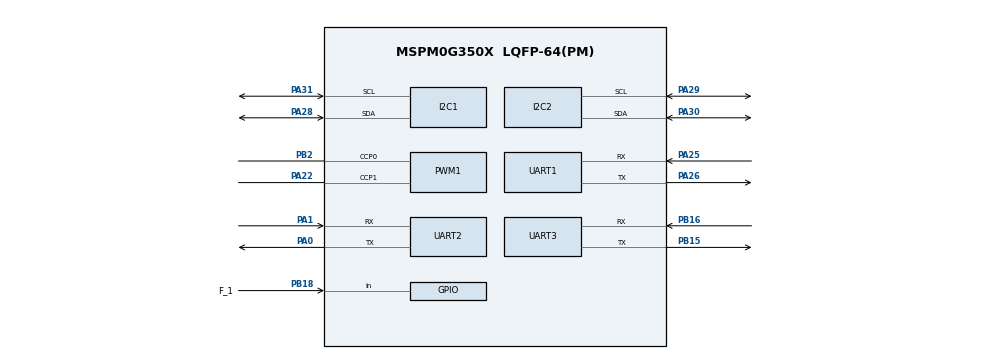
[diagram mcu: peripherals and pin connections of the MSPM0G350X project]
/**
 * @cliArgs --device "MSPM0G350X" --part "Default" --package "LQFP-64(PM)" --product "mspm0_sdk@2.04.00.06"
 * @versions {"tool":"1.24.0+4110"}
 */

/**
 * Import the modules used in this configuration.
 */
const GPIO    = scripting.addModule("/ti/driverlib/GPIO", {}, false);
const GPIO1   = GPIO.addInstance();
const GPIO2   = GPIO.addInstance();
const GPIO3   = GPIO.addInstance();
const GPIO4   = GPIO.addInstance();
const GPIO5   = GPIO.addInstance();
const GPIO6   = GPIO.addInstance();
const I2C     = scripting.addModule("/ti/driverlib/I2C", {}, false);
const I2C1    = I2C.addInstance();
const I2C2    = I2C.addInstance();
const PWM     = scripting.addModule("/ti/driverlib/PWM", {}, false);
const PWM1    = PWM.addInstance();
const SYSCTL  = scripting.addModule("/ti/driverlib/SYSCTL");
const SYSTICK = scripting.addModule("/ti/driverlib/SYSTICK");
const TIMER   = scripting.addModule("/ti/driverlib/TIMER", {}, false);
const TIMER1  = TIMER.addInstance();
const UART    = scripting.addModule("/ti/driverlib/UART", {}, false);
const UART1   = UART.addInstance();
const UART2   = UART.addInstance();
const UART3   = UART.addInstance();

/**
 * Write custom configuration values to the imported modules.
 */
const divider7       = system.clockTree["PLL_PDIV"];
divider7.divideValue = 8;

const divider9       = system.clockTree["UDIV"];
divider9.divideValue = 2;

const gate7  = system.clockTree["MFCLKGATE"];
gate7.enable = true;

const multiplier2         = system.clockTree["PLL_QDIV"];
multiplier2.multiplyValue = 40;

const mux8       = system.clockTree["HSCLKMUX"];
mux8.inputSelect = "HSCLKMUX_SYSPLL0";

const pinFunction4     = system.clockTree["HFXT"];
pinFunction4.inputFreq = 40;

GPIO1.$name                          = "GPIO_MOTOR_CONTROL";
GPIO1.associatedPins.create(4);
GPIO1.associatedPins[0].$name        = "left_IN1";
GPIO1.associatedPins[0].assignedPort = "PORTA";
GPIO1.associatedPins[0].assignedPin  = "12";
GPIO1.associatedPins[1].$name        = "left_IN2";
GPIO1.associatedPins[1].assignedPort = "PORTA";
GPIO1.associatedPins[1].assignedPin  = "13";
GPIO1.associatedPins[2].$name        = "right_IN1";
GPIO1.associatedPins[2].assignedPin  = "17";
GPIO1.associatedPins[2].assignedPort = "PORTA";
GPIO1.associatedPins[3].$name        = "right_IN2";
GPIO1.associatedPins[3].assignedPin  = "24";
GPIO1.associatedPins[3].assignedPort = "PORTA";

const Board = scripting.addModule("/ti/driverlib/Board", {}, false);

GPIO2.$name                               = "GPIO_ENCODER_L";
GPIO2.associatedPins.create(2);
GPIO2.associatedPins[0].direction         = "INPUT";
GPIO2.associatedPins[0].internalResistor  = "PULL_DOWN";
GPIO2.associatedPins[0].assignedPort      = "PORTB";
GPIO2.associatedPins[0].assignedPin       = "0";
GPIO2.associatedPins[0].interruptEn       = true;
GPIO2.associatedPins[0].interruptPriority = "0";
GPIO2.associatedPins[0].polarity          = "RISE";
GPIO2.associatedPins[0].$name             = "LEFT_A";
GPIO2.associatedPins[1].direction         = "INPUT";
GPIO2.associatedPins[1].internalResistor  = "PULL_DOWN";
GPIO2.associatedPins[1].assignedPort      = "PORTB";
GPIO2.associatedPins[1].assignedPin       = "14";
GPIO2.associatedPins[1].$name             = "LEFT_B";
GPIO2.associatedPins[1].interruptEn       = true;
GPIO2.associatedPins[1].interruptPriority = "0";
GPIO2.associatedPins[1].polarity          = "RISE";

GPIO3.$name                               = "GPIO_ENCODER_R";
GPIO3.associatedPins.create(2);
GPIO3.associatedPins[0].$name             = "RIGHT_A";
GPIO3.associatedPins[0].direction         = "INPUT";
GPIO3.associatedPins[0].internalResistor  = "PULL_DOWN";
GPIO3.associatedPins[0].interruptEn       = true;
GPIO3.associatedPins[0].interruptPriority = "0";
GPIO3.associatedPins[0].polarity          = "RISE";
GPIO3.associatedPins[0].assignedPort      = "PORTA";
GPIO3.associatedPins[0].assignedPin       = "7";
GPIO3.associatedPins[1].$name             = "RIGHT_B";
GPIO3.associatedPins[1].assignedPort      = "PORTB";
GPIO3.associatedPins[1].assignedPin       = "20";
GPIO3.associatedPins[1].direction         = "INPUT";
GPIO3.associatedPins[1].internalResistor  = "PULL_DOWN";
GPIO3.associatedPins[1].interruptEn       = true;
GPIO3.associatedPins[1].interruptPriority = "0";
GPIO3.associatedPins[1].polarity          = "RISE";

GPIO4.$name                              = "GPIO_CHOOSETOPIC";
GPIO4.associatedPins.create(2);
GPIO4.associatedPins[0].$name            = "Confirm";
GPIO4.associatedPins[0].direction        = "INPUT";
GPIO4.associatedPins[0].assignedPort     = "PORTB";
GPIO4.associatedPins[0].internalResistor = "PULL_UP";
GPIO4.associatedPins[0].assignedPin      = "4";
GPIO4.associatedPins[1].$name            = "ChooseStart";
GPIO4.associatedPins[1].direction        = "INPUT";
GPIO4.associatedPins[1].assignedPort     = "PORTB";
GPIO4.associatedPins[1].internalResistor = "PULL_UP";
GPIO4.associatedPins[1].assignedPin      = "5";

GPIO5.$name                               = "GPIO_GRAYSENSOR";
GPIO5.associatedPins.create(12);
GPIO5.associatedPins[0].$name             = "O1";
GPIO5.associatedPins[0].direction         = "INPUT";
GPIO5.associatedPins[0].internalResistor  = "PULL_DOWN";
GPIO5.associatedPins[0].assignedPort      = "PORTB";
GPIO5.associatedPins[0].assignedPin       = "27";
GPIO5.associatedPins[1].$name             = "O2";
GPIO5.associatedPins[1].direction         = "INPUT";
GPIO5.associatedPins[1].internalResistor  = "PULL_DOWN";
GPIO5.associatedPins[1].assignedPort      = "PORTB";
GPIO5.associatedPins[1].assignedPin       = "12";
GPIO5.associatedPins[2].$name             = "O3";
GPIO5.associatedPins[2].direction         = "INPUT";
GPIO5.associatedPins[2].assignedPort      = "PORTB";
GPIO5.associatedPins[2].internalResistor  = "PULL_DOWN";
GPIO5.associatedPins[2].assignedPin       = "13";
GPIO5.associatedPins[3].$name             = "O4";
GPIO5.associatedPins[3].direction         = "INPUT";
GPIO5.associatedPins[3].internalResistor  = "PULL_DOWN";
GPIO5.associatedPins[3].assignedPort      = "PORTB";
GPIO5.associatedPins[3].assignedPin       = "7";
GPIO5.associatedPins[4].$name             = "O5";
GPIO5.associatedPins[4].direction         = "INPUT";
GPIO5.associatedPins[4].internalResistor  = "PULL_DOWN";
GPIO5.associatedPins[4].assignedPort      = "PORTB";
GPIO5.associatedPins[4].assignedPin       = "9";
GPIO5.associatedPins[5].$name             = "O6";
GPIO5.associatedPins[5].direction         = "INPUT";
GPIO5.associatedPins[5].internalResistor  = "PULL_DOWN";
GPIO5.associatedPins[5].assignedPort      = "PORTB";
GPIO5.associatedPins[5].assignedPin       = "26";
GPIO5.associatedPins[6].$name             = "O7";
GPIO5.associatedPins[6].direction         = "INPUT";
GPIO5.associatedPins[6].internalResistor  = "PULL_DOWN";
GPIO5.associatedPins[6].assignedPort      = "PORTB";
GPIO5.associatedPins[6].assignedPin       = "17";
GPIO5.associatedPins[7].$name             = "O8";
GPIO5.associatedPins[7].direction         = "INPUT";
GPIO5.associatedPins[7].internalResistor  = "PULL_DOWN";
GPIO5.associatedPins[7].assignedPort      = "PORTB";
GPIO5.associatedPins[7].assignedPin       = "19";
GPIO5.associatedPins[8].$name             = "O9";
GPIO5.associatedPins[8].direction         = "INPUT";
GPIO5.associatedPins[8].internalResistor  = "PULL_DOWN";
GPIO5.associatedPins[8].assignedPort      = "PORTB";
GPIO5.associatedPins[8].assignedPin       = "21";
GPIO5.associatedPins[9].$name             = "O10";
GPIO5.associatedPins[9].direction         = "INPUT";
GPIO5.associatedPins[9].assignedPort      = "PORTB";
GPIO5.associatedPins[9].assignedPin       = "10";
GPIO5.associatedPins[9].internalResistor  = "PULL_DOWN";
GPIO5.associatedPins[10].$name            = "O11";
GPIO5.associatedPins[10].direction        = "INPUT";
GPIO5.associatedPins[10].internalResistor = "PULL_DOWN";
GPIO5.associatedPins[10].assignedPort     = "PORTB";
GPIO5.associatedPins[10].assignedPin      = "11";
GPIO5.associatedPins[11].$name            = "O12";
GPIO5.associatedPins[11].direction        = "INPUT";
GPIO5.associatedPins[11].assignedPort     = "PORTB";
GPIO5.associatedPins[11].assignedPin      = "24";
GPIO5.associatedPins[11].internalResistor = "PULL_DOWN";

GPIO6.$name                          = "GPIO_FUN";
GPIO6.associatedPins.create(2);
GPIO6.associatedPins[0].$name        = "F_1";
GPIO6.associatedPins[0].direction    = "INPUT";
GPIO6.associatedPins[0].assignedPort = "PORTB";
GPIO6.associatedPins[0].assignedPin  = "18";
GPIO6.associatedPins[0].pin.$assign  = "PB18";
GPIO6.associatedPins[1].$name        = "F_2";
GPIO6.associatedPins[1].direction    = "INPUT";
GPIO6.associatedPins[1].assignedPort = "PORTB";
GPIO6.associatedPins[1].assignedPin  = "22";

I2C1.$name                             = "I2C_MPU6050";
I2C1.basicEnableController             = true;
I2C1.basicControllerStandardBusSpeed   = "Fast";
I2C1.peripheral.sdaPin.$assign         = "PA28";
I2C1.peripheral.sclPin.$assign         = "PA31";
I2C1.sdaPinConfig.hideOutputInversion  = scripting.forceWrite(false);
I2C1.sdaPinConfig.onlyInternalResistor = scripting.forceWrite(false);
I2C1.sdaPinConfig.passedPeripheralType = scripting.forceWrite("Digital");
I2C1.sdaPinConfig.$name                = "ti_driverlib_gpio_GPIOPinGeneric10";
I2C1.sclPinConfig.hideOutputInversion  = scripting.forceWrite(false);
I2C1.sclPinConfig.onlyInternalResistor = scripting.forceWrite(false);
I2C1.sclPinConfig.passedPeripheralType = scripting.forceWrite("Digital");
I2C1.sclPinConfig.$name                = "ti_driverlib_gpio_GPIOPinGeneric11";

I2C2.$name                             = "I2C_OLED";
I2C2.basicEnableController             = true;
I2C2.basicControllerStandardBusSpeed   = "Fast";
I2C2.peripheral.sdaPin.$assign         = "PA30";
I2C2.peripheral.sclPin.$assign         = "PA29";
I2C2.sdaPinConfig.hideOutputInversion  = scripting.forceWrite(false);
I2C2.sdaPinConfig.onlyInternalResistor = scripting.forceWrite(false);
I2C2.sdaPinConfig.passedPeripheralType = scripting.forceWrite("Digital");
I2C2.sdaPinConfig.$name                = "ti_driverlib_gpio_GPIOPinGeneric12";
I2C2.sclPinConfig.hideOutputInversion  = scripting.forceWrite(false);
I2C2.sclPinConfig.onlyInternalResistor = scripting.forceWrite(false);
I2C2.sclPinConfig.passedPeripheralType = scripting.forceWrite("Digital");
I2C2.sclPinConfig.$name                = "ti_driverlib_gpio_GPIOPinGeneric13";

PWM1.$name                              = "Motor_PWM";
PWM1.timerCount                         = 2000;
PWM1.peripheral.$assign                 = "TIMG6";
PWM1.peripheral.ccp0Pin.$assign         = "PB2";
PWM1.peripheral.ccp1Pin.$assign         = "PA22";
PWM1.PWM_CHANNEL_0.$name                = "ti_driverlib_pwm_PWMTimerCC0";
PWM1.PWM_CHANNEL_1.$name                = "ti_driverlib_pwm_PWMTimerCC1";
PWM1.ccp0PinConfig.$name                = "ti_driverlib_gpio_GPIOPinGeneric4";
PWM1.ccp0PinConfig.direction            = scripting.forceWrite("OUTPUT");
PWM1.ccp0PinConfig.hideOutputInversion  = scripting.forceWrite(false);
PWM1.ccp0PinConfig.onlyInternalResistor = scripting.forceWrite(false);
PWM1.ccp0PinConfig.passedPeripheralType = scripting.forceWrite("Digital");
PWM1.ccp1PinConfig.$name                = "ti_driverlib_gpio_GPIOPinGeneric5";
PWM1.ccp1PinConfig.direction            = scripting.forceWrite("OUTPUT");
PWM1.ccp1PinConfig.hideOutputInversion  = scripting.forceWrite(false);
PWM1.ccp1PinConfig.onlyInternalResistor = scripting.forceWrite(false);
PWM1.ccp1PinConfig.passedPeripheralType = scripting.forceWrite("Digital");

SYSCTL.forceDefaultClkConfig = true;
SYSCTL.clockTreeEn           = true;

SYSTICK.periodEnable      = true;
SYSTICK.interruptEnable   = true;
SYSTICK.systickEnable     = true;
SYSTICK.interruptPriority = "1";
SYSTICK.period            = 80000;

TIMER1.$name = "TIMER_0";

UART1.enabledInterrupts                = ["RX"];
UART1.interruptPriority                = "0";
UART1.$name                            = "UART_k230";
UART1.uartClkSrc                       = "MFCLK";
UART1.targetBaudRate                   = 115200;
UART1.peripheral.$assign               = "UART3";
UART1.peripheral.rxPin.$assign         = "PA25";
UART1.peripheral.txPin.$assign         = "PA26";
UART1.txPinConfig.direction            = scripting.forceWrite("OUTPUT");
UART1.txPinConfig.hideOutputInversion  = scripting.forceWrite(false);
UART1.txPinConfig.onlyInternalResistor = scripting.forceWrite(false);
UART1.txPinConfig.passedPeripheralType = scripting.forceWrite("Digital");
UART1.txPinConfig.$name                = "ti_driverlib_gpio_GPIOPinGeneric0";
UART1.rxPinConfig.hideOutputInversion  = scripting.forceWrite(false);
UART1.rxPinConfig.onlyInternalResistor = scripting.forceWrite(false);
UART1.rxPinConfig.passedPeripheralType = scripting.forceWrite("Digital");
UART1.rxPinConfig.$name                = "ti_driverlib_gpio_GPIOPinGeneric1";

UART2.enabledInterrupts                = ["RX"];
UART2.$name                            = "UART_Debugger";
UART2.targetBaudRate                   = 115200;
UART2.peripheral.$assign               = "UART0";
UART2.peripheral.rxPin.$assign         = "PA1";
UART2.peripheral.txPin.$assign         = "PA0";
UART2.txPinConfig.direction            = scripting.forceWrite("OUTPUT");
UART2.txPinConfig.hideOutputInversion  = scripting.forceWrite(false);
UART2.txPinConfig.onlyInternalResistor = scripting.forceWrite(false);
UART2.txPinConfig.passedPeripheralType = scripting.forceWrite("Digital");
UART2.txPinConfig.$name                = "ti_driverlib_gpio_GPIOPinGeneric2";
UART2.rxPinConfig.hideOutputInversion  = scripting.forceWrite(false);
UART2.rxPinConfig.onlyInternalResistor = scripting.forceWrite(false);
UART2.rxPinConfig.passedPeripheralType = scripting.forceWrite("Digital");
UART2.rxPinConfig.$name                = "ti_driverlib_gpio_GPIOPinGeneric3";

UART3.enabledInterrupts                = ["RX"];
UART3.$name                            = "UART_StepperCMD";
UART3.targetBaudRate                   = 115200;
UART3.peripheral.$assign               = "UART2";
UART3.peripheral.rxPin.$assign         = "PB16";
UART3.peripheral.txPin.$assign         = "PB15";
UART3.txPinConfig.direction            = scripting.forceWrite("OUTPUT");
UART3.txPinConfig.hideOutputInversion  = scripting.forceWrite(false);
UART3.txPinConfig.onlyInternalResistor = scripting.forceWrite(false);
UART3.txPinConfig.passedPeripheralType = scripting.forceWrite("Digital");
UART3.txPinConfig.$name                = "ti_driverlib_gpio_GPIOPinGeneric8";
UART3.rxPinConfig.hideOutputInversion  = scripting.forceWrite(false);
UART3.rxPinConfig.onlyInternalResistor = scripting.forceWrite(false);
UART3.rxPinConfig.passedPeripheralType = scripting.forceWrite("Digital");
UART3.rxPinConfig.$name                = "ti_driverlib_gpio_GPIOPinGeneric9";

/**
 * Pinmux solution for unlocked pins/peripherals. This ensures that minor changes to the automatic solver in a future
 * version of the tool will not impact the pinmux you originally saw.  These lines can be completely deleted in order to
 * re-solve from scratch.
 */
GPIO1.associatedPins[0].pin.$suggestSolution  = "PA12";
GPIO1.associatedPins[1].pin.$suggestSolution  = "PA13";
GPIO1.associatedPins[2].pin.$suggestSolution  = "PA17";
GPIO1.associatedPins[3].pin.$suggestSolution  = "PA24";
Board.peripheral.$suggestSolution             = "DEBUGSS";
Board.peripheral.swclkPin.$suggestSolution    = "PA20";
Board.peripheral.swdioPin.$suggestSolution    = "PA19";
GPIO2.associatedPins[0].pin.$suggestSolution  = "PB0";
GPIO2.associatedPins[1].pin.$suggestSolution  = "PB14";
GPIO3.associatedPins[0].pin.$suggestSolution  = "PA7";
GPIO3.associatedPins[1].pin.$suggestSolution  = "PB20";
GPIO4.associatedPins[0].pin.$suggestSolution  = "PB4";
GPIO4.associatedPins[1].pin.$suggestSolution  = "PB5";
GPIO5.associatedPins[0].pin.$suggestSolution  = "PB27";
GPIO5.associatedPins[1].pin.$suggestSolution  = "PB12";
GPIO5.associatedPins[2].pin.$suggestSolution  = "PB13";
GPIO5.associatedPins[3].pin.$suggestSolution  = "PB7";
GPIO5.associatedPins[4].pin.$suggestSolution  = "PB9";
GPIO5.associatedPins[5].pin.$suggestSolution  = "PB26";
GPIO5.associatedPins[6].pin.$suggestSolution  = "PB17";
GPIO5.associatedPins[7].pin.$suggestSolution  = "PB19";
GPIO5.associatedPins[8].pin.$suggestSolution  = "PB21";
GPIO5.associatedPins[9].pin.$suggestSolution  = "PB10";
GPIO5.associatedPins[10].pin.$suggestSolution = "PB11";
GPIO5.associatedPins[11].pin.$suggestSolution = "PB24";
GPIO6.associatedPins[1].pin.$suggestSolution  = "PB22";
I2C1.peripheral.$suggestSolution              = "I2C0";
I2C2.peripheral.$suggestSolution              = "I2C1";
TIMER1.peripheral.$suggestSolution            = "TIMA0";
